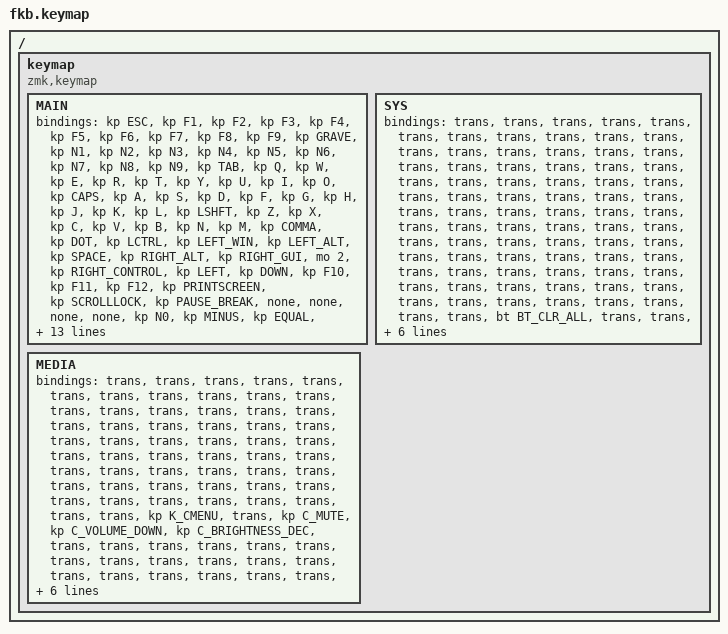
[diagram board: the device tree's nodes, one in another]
#include <behaviors.dtsi>
#include <dt-bindings/zmk/bt.h>
#include <dt-bindings/zmk/keys.h>

/ {
    keymap {
        compatible = "zmk,keymap";

        MAIN {
            bindings = <
&kp ESC  &kp F1  &kp F2  &kp F3  &kp F4  &kp F5  &kp F6  &kp F7  &kp F8  &kp F9  &kp GRAVE  &kp N1  &kp N2  &kp N3  &kp N4  &kp N5  &kp N6  &kp N7  &kp N8  &kp N9  &kp TAB  &kp Q  &kp W  &kp E  &kp R  &kp T  &kp Y  &kp U  &kp I  &kp O  &kp CAPS  &kp A  &kp S  &kp D  &kp F  &kp G  &kp H  &kp J  &kp K  &kp L  &kp LSHFT  &kp Z  &kp X  &kp C  &kp V  &kp B  &kp N  &kp M  &kp COMMA  &kp DOT  &kp LCTRL  &kp LEFT_WIN  &kp LEFT_ALT  &kp SPACE  &kp RIGHT_ALT  &kp RIGHT_GUI  &mo 2  &kp RIGHT_CONTROL  &kp LEFT  &kp DOWN  &kp F10  &kp F11  &kp F12  &kp PRINTSCREEN  &kp SCROLLLOCK  &kp PAUSE_BREAK  &none  &none  &none  &none  &kp N0  &kp MINUS  &kp EQUAL  &kp BACKSPACE  &kp INS  &kp HOME  &kp PAGE_UP  &kp KP_NUMLOCK  &kp KP_SLASH  &kp KP_MULTIPLY  &kp P  &kp LEFT_BRACKET  &kp RIGHT_BRACKET  &kp BACKSLASH  &kp DELETE  &kp END  &kp PAGE_DOWN  &kp KP_NUMBER_7  &kp KP_NUMBER_8  &kp KP_NUMBER_9  &kp SEMICOLON  &kp SQT  &kp ENTER  &kp KP_NUMBER_4  &kp KP_NUMBER_5  &kp KP_NUMBER_6  &kp KP_PLUS  &kp KP_MINUS  &none  &none  &kp SLASH  &kp RIGHT_SHIFT  &kp UP  &kp KP_NUMBER_1  &kp KP_NUMBER_2  &kp KP_NUMBER_3  &kp KP_ENTER  &lt 1 KP_DOT  &kp KP_NUMBER_0  &kp RIGHT
            >;
        };

        SYS {
            bindings = <
&trans  &trans  &trans  &trans  &trans  &trans  &trans  &trans  &trans  &trans  &trans  &trans  &trans  &trans  &trans  &trans  &trans  &trans  &trans  &trans  &trans  &trans  &trans  &trans  &trans  &trans  &trans  &trans  &trans  &trans  &trans  &trans  &trans  &trans  &trans  &trans  &trans  &trans  &trans  &trans  &trans  &trans  &trans  &trans  &trans  &trans  &trans  &trans  &trans  &trans  &trans  &trans  &trans  &trans  &trans  &trans  &trans  &trans  &trans  &trans  &trans  &trans  &trans  &trans  &trans  &trans  &trans  &trans  &trans  &trans  &trans  &trans  &trans  &trans  &trans  &trans  &trans  &trans  &trans  &bt BT_CLR_ALL  &trans  &trans  &trans  &trans  &trans  &trans  &trans  &trans  &trans  &trans  &trans  &trans  &trans  &trans  &trans  &trans  &trans  &trans  &trans  &trans  &trans  &trans  &trans  &bt BT_SEL 2  &bt BT_SEL 3  &bt BT_SEL 4  &bt BT_SEL 1  &trans  &bt BT_SEL 0  &trans
            >;
        };

        MEDIA {
            bindings = <
&trans  &trans  &trans  &trans  &trans  &trans  &trans  &trans  &trans  &trans  &trans  &trans  &trans  &trans  &trans  &trans  &trans  &trans  &trans  &trans  &trans  &trans  &trans  &trans  &trans  &trans  &trans  &trans  &trans  &trans  &trans  &trans  &trans  &trans  &trans  &trans  &trans  &trans  &trans  &trans  &trans  &trans  &trans  &trans  &trans  &trans  &trans  &trans  &trans  &trans  &trans  &trans  &trans  &trans  &trans  &kp K_CMENU  &trans  &kp C_MUTE  &kp C_VOLUME_DOWN  &kp C_BRIGHTNESS_DEC  &trans  &trans  &trans  &trans  &trans  &trans  &trans  &trans  &trans  &trans  &trans  &trans  &trans  &trans  &trans  &trans  &trans  &trans  &trans  &trans  &trans  &trans  &trans  &trans  &trans  &trans  &trans  &trans  &trans  &trans  &trans  &trans  &trans  &trans  &trans  &trans  &trans  &trans  &trans  &trans  &trans  &trans  &kp C_BRIGHTNESS_INC  &trans  &trans  &trans  &trans  &trans  &trans  &kp C_VOLUME_UP
            >;
        };
    };
};
